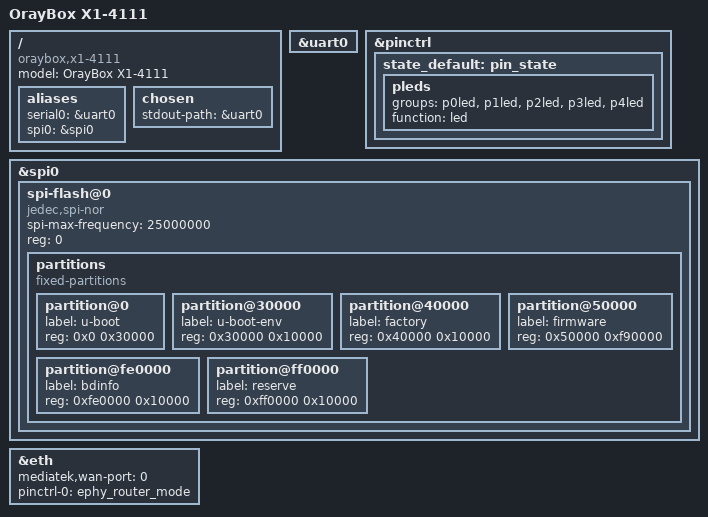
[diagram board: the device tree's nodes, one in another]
// SPDX-License-Identifier: GPL-2.0
/*
 * OrayBox X1-4111 (MT7628) — 由 oraybox/tools/gen-mtmips-dts.py 自动派生，未上机验证
 *
 * 证据来源: 内核 DTB 直读（oraybox-x1-4111-6.5.0-sysupgrade-stable-v1.0_20240301.bin）
 *   RAM      : 128MB
 *   console  : console=ttyS0,115200
 *   MAC      : partition@4 偏移 0x9
 *   按键/LED : oraybox:red:status=&gpio0 1, oraybox:blue:status=&gpio0 5, oraybox:white:status=&gpio0 12, reset=&gpio0 6
 *
 * 分区表照抄固件 DTB；u-boot 镜像必须小于 u-boot 分区，CI 里有体积守卫。
 */

/dts-v1/;

#include "mt7628a.dtsi"

/ {
	compatible = "oraybox,x1-4111", "ralink,mt7628a-soc";
	model = "OrayBox X1-4111";

	aliases {
		serial0 = &uart0;
		spi0 = &spi0;
	};

	chosen {
		stdout-path = &uart0;
	};
};

&uart0 {
	status = "okay";
};

&pinctrl {
	state_default: pin_state {
		pleds {
			groups = "p0led", "p1led", "p2led", "p3led", "p4led";
			function = "led";
		};
	};
};

&spi0 {
	status = "okay";

	spi-flash@0 {
		compatible = "jedec,spi-nor";
		spi-max-frequency = <25000000>;
		reg = <0>;

		partitions {
			compatible = "fixed-partitions";
			#address-cells = <1>;
			#size-cells = <1>;

			partition@0 {
				label = "u-boot";
				reg = <0x0 0x30000>;  /* 只读 */
			};

			partition@30000 {
				label = "u-boot-env";
				reg = <0x30000 0x10000>;
			};

			partition@40000 {
				label = "factory";
				reg = <0x40000 0x10000>;  /* 只读 */
			};

			partition@50000 {
				label = "firmware";
				reg = <0x50000 0xf90000>;
			};

			partition@fe0000 {
				label = "bdinfo";
				reg = <0xfe0000 0x10000>;
			};

			partition@ff0000 {
				label = "reserve";
				reg = <0xff0000 0x10000>;
			};
		};
	};
};

&eth {
	mediatek,wan-port = <0>;

	pinctrl-names = "default";
	pinctrl-0 = <&ephy_router_mode>;
};
